AUTOSAR XML (schema 4-3-0)
standard types defined: uint8, uint8_DataConstr
package /ComponentTypes
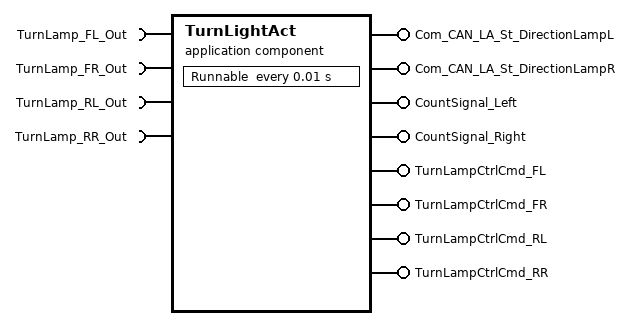
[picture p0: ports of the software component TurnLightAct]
  application sw component type TurnLightAct
    8 x provide port:
      Com_CAN_LA_St_DirectionLampL: nonqueued-sender-com-spec{data-element=Com_CAN_LA_St_DirectionLampL/Signal, init-value=0}, provided-interface=Com_CAN_LA_St_DirectionLampL
      Com_CAN_LA_St_DirectionLampR: nonqueued-sender-com-spec{data-element=Com_CAN_LA_St_DirectionLampR/Signal, init-value=0}, provided-interface=Com_CAN_LA_St_DirectionLampR
      CountSignal_Left: nonqueued-sender-com-spec{data-element=CountSignal_Left/Signal, init-value=0}, provided-interface=CountSignal_Left
      CountSignal_Right: nonqueued-sender-com-spec{data-element=CountSignal_Right/Signal, init-value=0}, provided-interface=CountSignal_Right
      TurnLampCtrlCmd_FL: nonqueued-sender-com-spec{data-element=TurnLampCtrlCmd_FL/Signal, init-value=0}, provided-interface=TurnLampCtrlCmd_FL
      TurnLampCtrlCmd_FR: nonqueued-sender-com-spec{data-element=TurnLampCtrlCmd_FR/Signal, init-value=0}, provided-interface=TurnLampCtrlCmd_FR
      TurnLampCtrlCmd_RL: nonqueued-sender-com-spec{data-element=TurnLampCtrlCmd_RL/Signal, init-value=0}, provided-interface=TurnLampCtrlCmd_RL
      TurnLampCtrlCmd_RR: nonqueued-sender-com-spec{data-element=TurnLampCtrlCmd_RR/Signal, init-value=0}, provided-interface=TurnLampCtrlCmd_RR
    4 x require port:
      TurnLamp_FL_Out: nonqueued-receiver-com-spec{data-element=TurnLamp_FL_Out/Signal, filter=data-filter-type=ALWAYS, init-value=0}, required-interface=TurnLamp_FL_Out
      TurnLamp_FR_Out: nonqueued-receiver-com-spec{data-element=TurnLamp_FR_Out/Signal, filter=data-filter-type=ALWAYS, init-value=0}, required-interface=TurnLamp_FR_Out
      TurnLamp_RL_Out: nonqueued-receiver-com-spec{data-element=TurnLamp_RL_Out/Signal, filter=data-filter-type=ALWAYS, init-value=0}, required-interface=TurnLamp_RL_Out
      TurnLamp_RR_Out: nonqueued-receiver-com-spec{data-element=TurnLamp_RR_Out/Signal, filter=data-filter-type=ALWAYS, init-value=0}, required-interface=TurnLamp_RR_Out
    behavior TurnLightAct_InternalBehavior
      timing event TMT_Runnable: start-on-event=Runnable, period=0.01
      runnable Runnable
        data-receive-point-by-arguments:
          4 x access:
            REC_TurnLamp_FL_Out_Signal: accessed-variable=TurnLamp_FL_Out.Signal
            REC_TurnLamp_FR_Out_Signal: accessed-variable=TurnLamp_FR_Out.Signal
            REC_TurnLamp_RL_Out_Signal: accessed-variable=TurnLamp_RL_Out.Signal
            REC_TurnLamp_RR_Out_Signal: accessed-variable=TurnLamp_RR_Out.Signal
        data-send-points:
          8 x access:
            SEND_Com_CAN_LA_St_DirectionLampL_Signal: accessed-variable=Com_CAN_LA_St_DirectionLampL.Signal
            SEND_Com_CAN_LA_St_DirectionLampR_Signal: accessed-variable=Com_CAN_LA_St_DirectionLampR.Signal
            SEND_CountSignal_Left_Signal: accessed-variable=CountSignal_Left.Signal
            SEND_CountSignal_Right_Signal: accessed-variable=CountSignal_Right.Signal
            SEND_TurnLampCtrlCmd_FL_Signal: accessed-variable=TurnLampCtrlCmd_FL.Signal
            SEND_TurnLampCtrlCmd_FR_Signal: accessed-variable=TurnLampCtrlCmd_FR.Signal
            SEND_TurnLampCtrlCmd_RL_Signal: accessed-variable=TurnLampCtrlCmd_RL.Signal
            SEND_TurnLampCtrlCmd_RR_Signal: accessed-variable=TurnLampCtrlCmd_RR.Signal
  swc implementation TurnLightAct_Implementation: behavior=TurnLightAct_InternalBehavior
    code-descriptors:
      code Default: artifact-descriptors=autosar-engineering-object={short-label=Default, category=SWSRC}
package /PortInterfaces
  12 x sender receiver interface:
    Com_CAN_LA_St_DirectionLampL: invalidation-policy{data-element=Com_CAN_LA_St_DirectionLampL/Signal, handle-invalid=DONT-INVALIDATE}
      data Signal: type=uint8
    Com_CAN_LA_St_DirectionLampR: invalidation-policy{data-element=Com_CAN_LA_St_DirectionLampR/Signal, handle-invalid=DONT-INVALIDATE}
      data Signal: type=uint8
    CountSignal_Left: invalidation-policy{data-element=CountSignal_Left/Signal, handle-invalid=DONT-INVALIDATE}
      data Signal: type=uint8
    CountSignal_Right: invalidation-policy{data-element=CountSignal_Right/Signal, handle-invalid=DONT-INVALIDATE}
      data Signal: type=uint8
    TurnLamp_FL_Out: invalidation-policy{data-element=TurnLamp_FL_Out/Signal, handle-invalid=DONT-INVALIDATE}
      data Signal: type=uint8
    TurnLamp_FR_Out: invalidation-policy{data-element=TurnLamp_FR_Out/Signal, handle-invalid=DONT-INVALIDATE}
      data Signal: type=uint8
    TurnLamp_RL_Out: invalidation-policy{data-element=TurnLamp_RL_Out/Signal, handle-invalid=DONT-INVALIDATE}
      data Signal: type=uint8
    TurnLamp_RR_Out: invalidation-policy{data-element=TurnLamp_RR_Out/Signal, handle-invalid=DONT-INVALIDATE}
      data Signal: type=uint8
    TurnLampCtrlCmd_FL: invalidation-policy{data-element=TurnLampCtrlCmd_FL/Signal, handle-invalid=DONT-INVALIDATE}
      data Signal: type=uint8
    TurnLampCtrlCmd_FR: invalidation-policy{data-element=TurnLampCtrlCmd_FR/Signal, handle-invalid=DONT-INVALIDATE}
      data Signal: type=uint8
    TurnLampCtrlCmd_RL: invalidation-policy{data-element=TurnLampCtrlCmd_RL/Signal, handle-invalid=DONT-INVALIDATE}
      data Signal: type=uint8
    TurnLampCtrlCmd_RR: invalidation-policy{data-element=TurnLampCtrlCmd_RR/Signal, handle-invalid=DONT-INVALIDATE}
      data Signal: type=uint8
